# MKW41Z4 register map
Vendor: Freescale Semiconductor, Inc.; Series: Kinetis_W; File version: 1.6
CPU: CM0PLUS r0p0, little endian, no MPU, no FPU, VTOR, 2 interrupt priority bits
Registers are 16-bit, read-write, no defined reset value unless marked. A register's access mark holds for its fields unless they carry their own. Offsets are from the block's base; [hi:lo] are bit positions; {n}, {i} and the like mark numbered series.

## XCVR_PHY_REGS — XCVR_PHY
Base 0x4005C400
0x00 PHY_PRE_REF0 32-bit reset 0xFDDDEB39 — PREAMBLE REFERENCE WAVEFORM 0
  [31:0] FSK_PREAMBLE_REF0 — Base preamble reference waveform containing sixteen 5-bit phase values
0x04 PRE_REF1 32-bit reset 0xBEFBFFFF — PREAMBLE REFERENCE WAVEFORM 1
  [31:0] FSK_PREAMBLE_REF1 — Base preamble reference waveform containing sixteen 5-bit phase values
0x08 PRE_REF2 32-bit reset 0xCE75 — PREAMBLE REFERENCE WAVEFORM 2
  [15:0] FSK_PREAMBLE_REF2 — Base preamble reference waveform containing sixteen 5-bit phase values
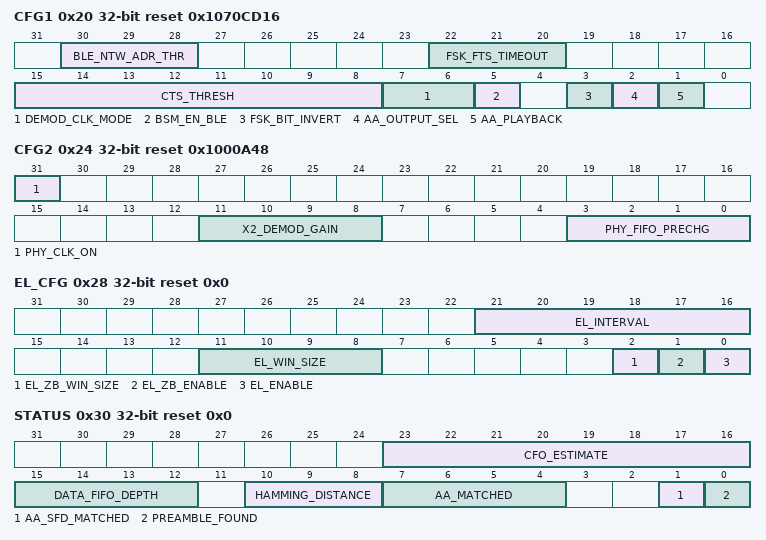
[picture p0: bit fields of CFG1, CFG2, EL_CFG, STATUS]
0x20 CFG1 32-bit reset 0x1070CD16 — PHY CONFIGURATION REGISTER 1
  [30:28] BLE_NTW_ADR_THR — BLE Network Address Match Bit Error Threshold
  [22:20] FSK_FTS_TIMEOUT
    {v}={v+4} symbols (v=0..7)
  [15:8] CTS_THRESH — CTS (Coarse Timing Search) Correlation Threshold
  [7:6] DEMOD_CLK_MODE — Demodulator Clock Mode
    0=Normal; 1=Demodulate all samples
  [5] BSM_EN_BLE — BLE Bit Streaming Mode Enable bit
    0=BSM for BLE disabled; 1=BSM for BLE enabled
  [3] FSK_BIT_INVERT
  [2] AA_OUTPUT_SEL — Access Address Output Select
    0=demodulated; 1=matched
  [1] AA_PLAYBACK — Access Address Playback
0x24 CFG2 32-bit reset 0x1000A48 — PHY CONFIGURATION REGISTER 2
  [31] PHY_CLK_ON — Force PHY Clock On (testmode)
    0=PHY clock is enabled by TSM output: rx_phy_en; 1=PHY clock is forced on at all times
  [11:8] X2_DEMOD_GAIN
  [3:0] PHY_FIFO_PRECHG — PHY FIFO Precharge Level
0x28 EL_CFG 32-bit reset 0x0 — PHY EARLY/LATE CONFIGURATION REGISTER
  [21:16] EL_INTERVAL
  [11:8] EL_WIN_SIZE
  [2] EL_ZB_WIN_SIZE
    0=2 symbols; 1=3 symbols
  [1] EL_ZB_ENABLE
    0=Disable Early/Late; 1=Enable Early/Late
  [0] EL_ENABLE
    0=Disable Early/Late; 1=Enable Early/Late
0x2C NTW_ADR_BSM 32-bit reset 0x0 — PHY NETWORK ADDRESS FOR BSM
0x30 STATUS 32-bit ro reset 0x0 — PHY STATUS REGISTER
  [23:16] CFO_ESTIMATE — Carrier Frequency Offset Estimate
  [15:12] DATA_FIFO_DEPTH
  [10:8] HAMMING_DISTANCE
  [7:4] AA_MATCHED — Access Address Matched
    0=No Network Address has matched; 1=Network Address 0 has matched; 2=Network Address 1 has matched; 4=Network Address 2 has matched; 8=Network Address 3 has matched
  [1] AA_SFD_MATCHED — Access Address or SFD Found
  [0] PREAMBLE_FOUND

## XCVR_ZBDEMOD_REGS — XCVR_ZBDEMOD
Base 0x4005C480
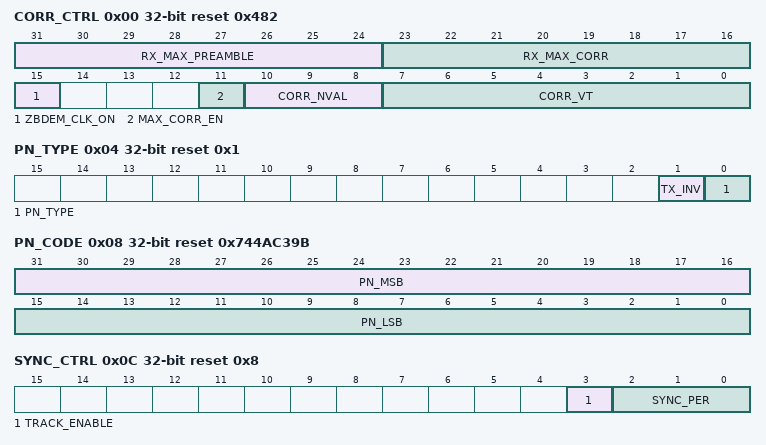
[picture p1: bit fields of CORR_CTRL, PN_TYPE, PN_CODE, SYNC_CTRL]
0x00 CORR_CTRL 32-bit reset 0x482 (reset mask 0xFFFF) — 802.15.4 DEMOD CORRELLATOR CONTROL
  [31:24] RX_MAX_PREAMBLE ro
  [23:16] RX_MAX_CORR ro
  [15] ZBDEM_CLK_ON — Force 802.15.4 Demodulator Clock On
    0=Normal Operation; 1=Force 802.15.4 Demodulator Clock On (debug purposes only)
  [11] MAX_CORR_EN
  [10:8] CORR_NVAL
  [7:0] CORR_VT
0x04 PN_TYPE 32-bit reset 0x1 — 802.15.4 DEMOD PN TYPE
  [1] TX_INV, [0] PN_TYPE
0x08 PN_CODE 32-bit reset 0x744AC39B — 802.15.4 DEMOD PN CODE
  [31:16] PN_MSB, [15:0] PN_LSB
0x0C SYNC_CTRL 32-bit reset 0x8 — 802.15.4 DEMOD SYMBOL SYNC CONTROL
  [3] TRACK_ENABLE
    0=symbol timing synchronization tracking disabled in Rx frontend; 1=symbol timing synchronization tracking enabled in Rx frontend (default)
  [2:0] SYNC_PER — Symbol Sync Tracking Period
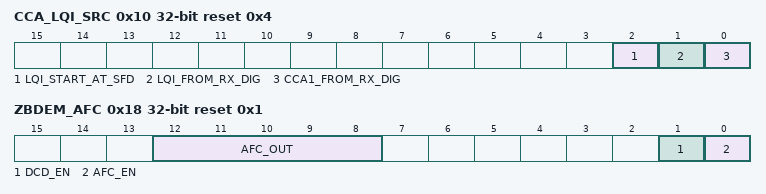
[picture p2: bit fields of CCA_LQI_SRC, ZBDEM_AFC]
0x10 CCA_LQI_SRC 32-bit reset 0x4 — 802.15.4 CCA/LQI SOURCE
  [2] LQI_START_AT_SFD — Select Start Point for LQI Computation
    0=Start LQI computation at Preamble Detection (similar to previous Freescale 802.15.4 products); 1=Start LQI computation at SFD (Start of Frame Delimiter) Detection
  [1] LQI_FROM_RX_DIG — Selects the Source of LQI (Link Quality Indicator) Information Provided to the 802.15.4 Link Layer
    0=Use the LQI information computed internally in the 802.15.4 Demod; 1=Use the LQI information computed by the RX Digital
  [0] CCA1_FROM_RX_DIG — Selects the Source of CCA1 (Clear Channel Assessment Mode 1) Information Provided to the 802.15.4 Link Layer
    0=Use the CCA1 information computed internally in the 802.15.4 Demod; 1=Use the CCA1 information computed by the RX Digital
0x14 FAD_THR 32-bit reset 0x82 — FAD CORRELATOR THRESHOLD
  [7:0] FAD_THR
0x18 ZBDEM_AFC 32-bit reset 0x1 (reset mask 0xFFFFE0FF) — 802.15.4 AFC STATUS
  [12:8] AFC_OUT ro
  [1] DCD_EN
    0=NCD Mode (default); 1=DCD Mode
  [0] AFC_EN
    0=AFC is disabled; 1=AFC is enabled
